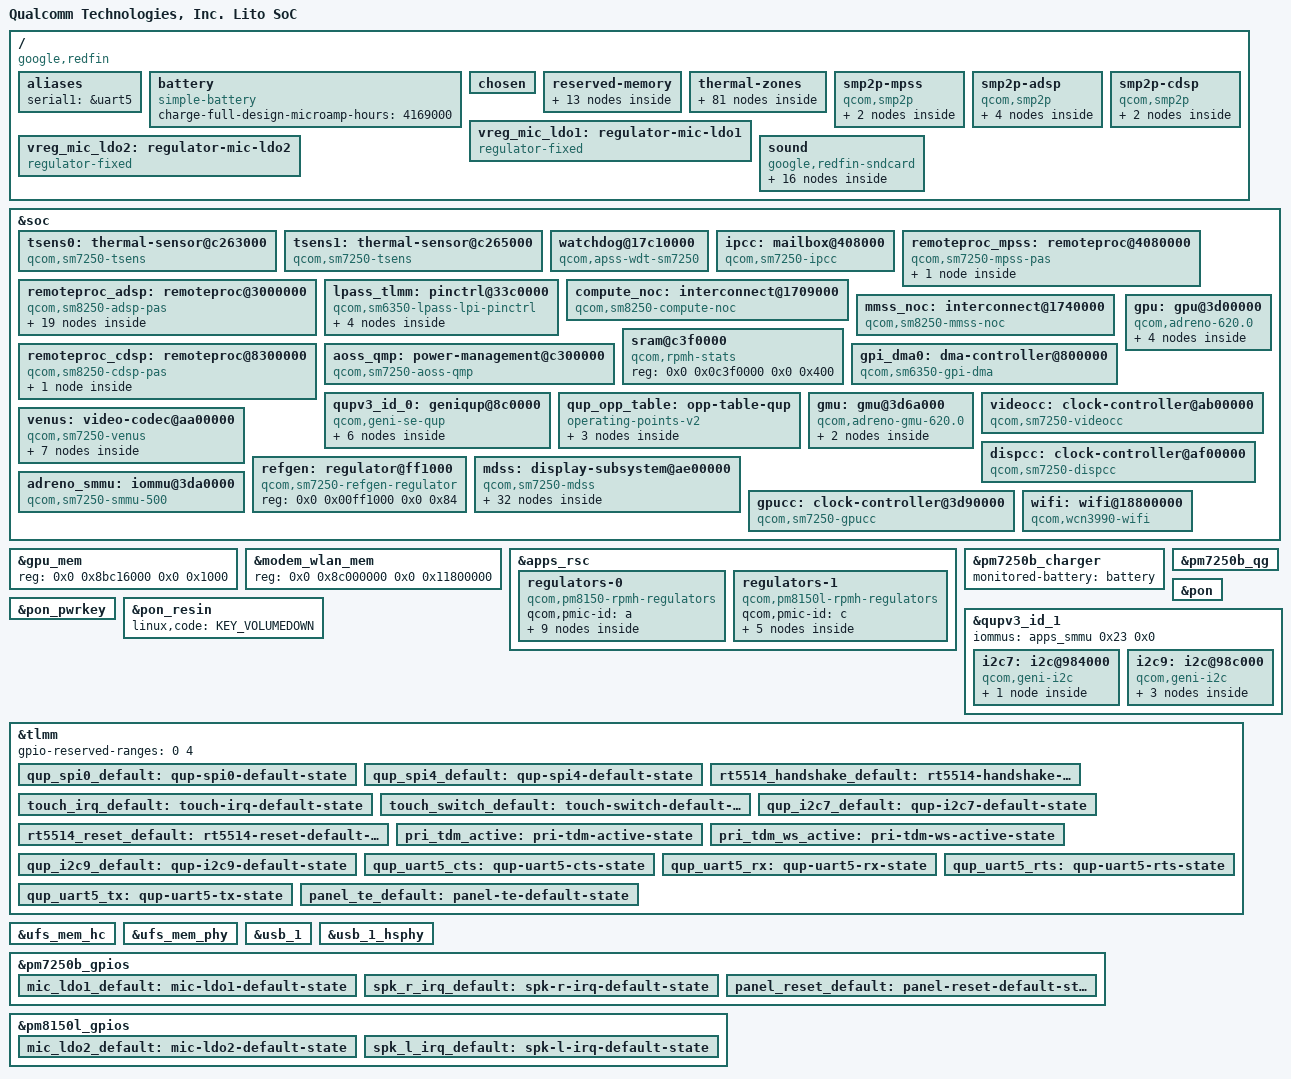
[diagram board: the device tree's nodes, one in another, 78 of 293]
// SPDX-License-Identifier: GPL-2.0-only
/*
 * Google Pixel 5 (redfin), SM7250. First-gate board file (P6.3): enough to
 * reach an initramfs over UFS + USB2 with a mainline kernel.
 *
 * Hardware values come from the DT the bootloader hands the stock 4.19
 * kernel (firmware/live.dtb: base DTB + dtbo overlay 25, Redfin PVT) and the
 * downstream sources (lito-redfin*.dtsi). See docs/research/mainline-boot.md.
 */
/dts-v1/;

#include <dt-bindings/dma/qcom-gpi.h>
#include <dt-bindings/arm/qcom,ids.h>
#include <dt-bindings/clock/qcom,dispcc-sm8250.h>
#include <dt-bindings/clock/qcom,dsi-phy-28nm.h>
#include <dt-bindings/clock/qcom,gpucc-sm8250.h>
#include <dt-bindings/clock/qcom,videocc-sm7250.h>
#include <dt-bindings/firmware/qcom,scm.h>
#include <dt-bindings/gpio/gpio.h>
#include <dt-bindings/input/input.h>
#include <dt-bindings/interconnect/qcom,sm8250.h>
#include <dt-bindings/interrupt-controller/arm-gic.h>
#include <dt-bindings/mailbox/qcom-ipcc.h>
#include <dt-bindings/pinctrl/qcom,pmic-gpio.h>
#include <dt-bindings/regulator/qcom,rpmh-regulator.h>
#include <dt-bindings/soc/qcom,apr.h>
#include <dt-bindings/sound/qcom,q6afe.h>
#include <dt-bindings/sound/qcom,q6asm.h>
#include "sm7250.dtsi"
#include "pm8150.dtsi"
#include "pm8150l.dtsi"

/* Live DT: qcom,pm7250b@2 and @3 on the SPMI bus */
#define PM7250B_SID 2
#define PM7250B_SID1 3
#include "pm7250b.dtsi"
#include "sm7250-google-redfin-dtbo-sink.dtsi"

/ {
	/*
	 * model, msm-id and board-id are exactly those of the stock base DTB
	 * in vendor_boot, which the bootloader is known to pick (Test 27).
	 * The dtbo overlay then replaces every existing root property: Linux
	 * sees model "Google Inc. MSM sm7250 v2 Redfin PVT" and compatible
	 * "google,redfin-sm7250", "qcom,sm7250" (live DT).
	 */
	model = "Qualcomm Technologies, Inc. Lito SoC";
	compatible = "google,redfin", "qcom,sm7250";
	chassis-type = "handset";
	qcom,msm-id = <QCOM_ID_SM7250 0x10000>, <440 0x10000>;
	qcom,board-id = <0 0>;

	/*
	 * Design capacity (downstream charge_full_design) and the cell's OCV
	 * tables, which qcom_qg needs. No voltage or current: qcom_smbx then
	 * keeps the float voltage the bootloader set (4.45 V downstream).
	 */
	aliases {
		/*
		 * qcom_geni_serial numbers high-speed UARTs after the highest
		 * serial alias; with none at all the port is refused ("Invalid
		 * line -19", Test 99).
		 */
		serial1 = &uart5;
	};

	battery: battery {
		compatible = "simple-battery";
		charge-full-design-microamp-hours = <4169000>;
		/*
		 * Generated at build time from firmware/live.dts by
		 * scripts/gen-battery-ocv.py (vendor data, not in git).
		 */
#include "sm7250-google-redfin-battery-ocv.dtsi"
	};

	/* The bootloader fills in bootargs, initrd, kaslr-seed (and cdt). */
	chosen {
	};

	reserved-memory {
		/*
		 * Fixed regions of the live DT that sm7250.dtsi does not reserve.
		 * The stock overlay's own carve-outs land in the sink, so all of
		 * them are repeated here.
		 */
		sec_apps_mem: sec-apps@808ff000 {
			reg = <0x0 0x808ff000 0x0 0x1000>;
			no-map;
		};

		qtee_apps_mem: qtee-apps@81e00000 {
			reg = <0x0 0x81e00000 0x0 0x2600000>;
			no-map;
		};

		pil_reserved_mem: pil-reserved@8bc17400 {
			reg = <0x0 0x8bc17400 0x0 0x3e8c00>;
			no-map;
		};

		/* Bootloader splash; also the display ramdump area */
		cont_splash_mem: cont-splash@a0000000 {
			reg = <0x0 0xa0000000 0x0 0x2300000>;
			no-map;
		};

		dfps_data_mem: dfps-data@a2300000 {
			reg = <0x0 0xa2300000 0x0 0x100000>;
			no-map;
		};

		debug_info_mem: debug-info@b7e01000 {
			reg = <0x0 0xb7e01000 0x0 0x40000>;
			no-map;
		};

		/*
		 * Stock ramoops, alt copy and metadata. Not used as pstore:
		 * neither a warm reboot nor a panic reboot keeps it (Test 28).
		 */
		ramoops_mem: ramoops@b7e41000 {
			reg = <0x0 0xb7e41000 0x0 0x400000>;
			no-map;
		};

		alt_ramoops_mem: alt-ramoops@b8241000 {
			reg = <0x0 0xb8241000 0x0 0x400000>;
			no-map;
		};

		/*
		 * Venus secure non-pixel pool: handed to VM CP_NON_PIXEL (0xb)
		 * at probe, so no-map. Encoder INTERNAL_PERSIST buffers come
		 * from it (64 KiB per 720p session).
		 */
		venus_np_mem: venus-non-pixel {
			size = <0x0 0x400000>;
			alignment = <0x0 0x100000>;
			no-map;
		};

		ramoops_meta_mem: ramoops-meta@b8641000 {
			reg = <0x0 0xb8641000 0x0 0x1000>;
			no-map;
		};

		ramdumplog_mem: ramdumplog@b8642000 {
			reg = <0x0 0xb8642000 0x0 0x10000>;
			no-map;
		};

		kregistry_mem: kregistry@c8000000 {
			reg = <0x0 0xc8000000 0x0 0x10000>;
			no-map;
		};

		/*
		 * Modem EFS buffer for rmtfs. Downstream allocates it at run time
		 * (live DT qcom,rmtfs_sharedmem: size only) and shares it with the
		 * modem (hyp_assign to HLOS + MSS_MSA); on redfin it lands at
		 * 0xf9900000 (downstream /sys/class/uio/uio0/maps/map0).
		 */
		rmtfs_mem: rmtfs@f9900000 {
			compatible = "qcom,rmtfs-mem";
			reg = <0x0 0xf9900000 0x0 0x280000>;
			no-map;

			qcom,client-id = <1>;
			qcom,vmid = <QCOM_SCM_VMID_MSS_MSA>;
		};
	};
};

&soc {
	/*
	 * The two TSENS controllers, as in the live DT (tsens@c222000 and
	 * tsens@c223000: SROT + TM regions, PDC 26/28 and 27/29). Their
	 * "tsens-0C" interrupt (PDC 20/21) is downstream-only.
	 */
	tsens0: thermal-sensor@c263000 {
		compatible = "qcom,sm7250-tsens", "qcom,tsens-v2";
		reg = <0x0 0x0c263000 0x0 0x1ff>,	/* TM */
		      <0x0 0x0c222000 0x0 0x1ff>;	/* SROT */
		#qcom,sensors = <15>;
		interrupts-extended = <&pdc 26 IRQ_TYPE_LEVEL_HIGH>,
				      <&pdc 28 IRQ_TYPE_LEVEL_HIGH>;
		interrupt-names = "uplow", "critical";
		#thermal-sensor-cells = <1>;
	};

	tsens1: thermal-sensor@c265000 {
		compatible = "qcom,sm7250-tsens", "qcom,tsens-v2";
		reg = <0x0 0x0c265000 0x0 0x1ff>,	/* TM */
		      <0x0 0x0c223000 0x0 0x1ff>;	/* SROT */
		#qcom,sensors = <12>;
		interrupts-extended = <&pdc 27 IRQ_TYPE_LEVEL_HIGH>,
				      <&pdc 29 IRQ_TYPE_LEVEL_HIGH>;
		interrupt-names = "uplow", "critical";
		#thermal-sensor-cells = <1>;
	};
};

/*
 * One zone per sensor, named and numbered as downstream
 * (vendor/qcom/lito-thermal.dtsi). Only a critical trip for now: 110 C
 * shuts the phone down. CPU throttling is the cpufreq-hw firmware's (LMh);
 * GPU and modem cooling come with those items.
 */
/ {
	thermal-zones {
		aoss0-thermal {
			thermal-sensors = <&tsens0 0>;

			trips {
				aoss0-crit {
					temperature = <110000>;
					hysteresis = <1000>;
					type = "critical";
				};
			};
		};

		cpu0-0-thermal {
			thermal-sensors = <&tsens0 1>;

			trips {
				cpu0-0-crit {
					temperature = <110000>;
					hysteresis = <1000>;
					type = "critical";
				};
			};
		};

		cpu0-1-thermal {
			thermal-sensors = <&tsens0 2>;

			trips {
				cpu0-1-crit {
					temperature = <110000>;
					hysteresis = <1000>;
					type = "critical";
				};
			};
		};

		cpu0-2-thermal {
			thermal-sensors = <&tsens0 3>;

			trips {
				cpu0-2-crit {
					temperature = <110000>;
					hysteresis = <1000>;
					type = "critical";
				};
			};
		};

		cpu0-3-thermal {
			thermal-sensors = <&tsens0 4>;

			trips {
				cpu0-3-crit {
					temperature = <110000>;
					hysteresis = <1000>;
					type = "critical";
				};
			};
		};

		cpu0-4-thermal {
			thermal-sensors = <&tsens0 5>;

			trips {
				cpu0-4-crit {
					temperature = <110000>;
					hysteresis = <1000>;
					type = "critical";
				};
			};
		};

		cpu0-5-thermal {
			thermal-sensors = <&tsens0 6>;

			trips {
				cpu0-5-crit {
					temperature = <110000>;
					hysteresis = <1000>;
					type = "critical";
				};
			};
		};

		cpuss0-thermal {
			thermal-sensors = <&tsens0 7>;

			trips {
				cpuss0-crit {
					temperature = <110000>;
					hysteresis = <1000>;
					type = "critical";
				};
			};
		};

		cpuss1-thermal {
			thermal-sensors = <&tsens0 8>;

			trips {
				cpuss1-crit {
					temperature = <110000>;
					hysteresis = <1000>;
					type = "critical";
				};
			};
		};

		cpu1-0-thermal {
			thermal-sensors = <&tsens0 9>;

			trips {
				cpu1-0-crit {
					temperature = <110000>;
					hysteresis = <1000>;
					type = "critical";
				};
			};
		};

		cpu1-1-thermal {
			thermal-sensors = <&tsens0 10>;

			trips {
				cpu1-1-crit {
					temperature = <110000>;
					hysteresis = <1000>;
					type = "critical";
				};
			};
		};

		cpu1-2-thermal {
			thermal-sensors = <&tsens0 11>;

			trips {
				cpu1-2-crit {
					temperature = <110000>;
					hysteresis = <1000>;
					type = "critical";
				};
			};
		};

		cpu1-3-thermal {
			thermal-sensors = <&tsens0 12>;

			trips {
				cpu1-3-crit {
					temperature = <110000>;
					hysteresis = <1000>;
					type = "critical";
				};
			};
		};

		gpuss0-thermal {
			thermal-sensors = <&tsens0 13>;

			trips {
				gpuss0-crit {
					temperature = <110000>;
					hysteresis = <1000>;
					type = "critical";
				};
			};
		};

		gpuss1-thermal {
			thermal-sensors = <&tsens0 14>;

			trips {
				gpuss1-crit {
					temperature = <110000>;
					hysteresis = <1000>;
					type = "critical";
				};
			};
		};

		aoss1-thermal {
			thermal-sensors = <&tsens1 0>;

			trips {
				aoss1-crit {
					temperature = <110000>;
					hysteresis = <1000>;
					type = "critical";
				};
			};
		};

		cwlan-thermal {
			thermal-sensors = <&tsens1 1>;

			trips {
				cwlan-crit {
					temperature = <110000>;
					hysteresis = <1000>;
					type = "critical";
				};
			};
		};

		video-thermal {
			thermal-sensors = <&tsens1 2>;

			trips {
				video-crit {
					temperature = <110000>;
					hysteresis = <1000>;
					type = "critical";
				};
			};
		};

		ddr-thermal {
			thermal-sensors = <&tsens1 3>;

			trips {
				ddr-crit {
					temperature = <110000>;
					hysteresis = <1000>;
					type = "critical";
				};
			};
		};

		q6-hvx-thermal {
			thermal-sensors = <&tsens1 4>;

			trips {
				q6-hvx-crit {
					temperature = <110000>;
					hysteresis = <1000>;
					type = "critical";
				};
			};
		};

		cmpss-thermal {
			thermal-sensors = <&tsens1 5>;

			trips {
				cmpss-crit {
					temperature = <110000>;
					hysteresis = <1000>;
					type = "critical";
				};
			};
		};

		npu-thermal {
			thermal-sensors = <&tsens1 6>;

			trips {
				npu-crit {
					temperature = <110000>;
					hysteresis = <1000>;
					type = "critical";
				};
			};
		};

		camera-thermal {
			thermal-sensors = <&tsens1 7>;

			trips {
				camera-crit {
					temperature = <110000>;
					hysteresis = <1000>;
					type = "critical";
				};
			};
		};

		mdm-vec-thermal {
			thermal-sensors = <&tsens1 8>;

			trips {
				mdm-vec-crit {
					temperature = <110000>;
					hysteresis = <1000>;
					type = "critical";
				};
			};
		};

		mdm-scl-thermal {
			thermal-sensors = <&tsens1 9>;

			trips {
				mdm-scl-crit {
					temperature = <110000>;
					hysteresis = <1000>;
					type = "critical";
				};
			};
		};

		mdm-core0-thermal {
			thermal-sensors = <&tsens1 10>;

			trips {
				mdm-core0-crit {
					temperature = <110000>;
					hysteresis = <1000>;
					type = "critical";
				};
			};
		};

		mdm-core1-thermal {
			thermal-sensors = <&tsens1 11>;

			trips {
				mdm-core1-crit {
					temperature = <110000>;
					hysteresis = <1000>;
					type = "critical";
				};
			};
		};
	};

	/* Live DT qcom,smp2p-mpss: SMEM items 435/428, IPCC client MPSS signal 2 */
	smp2p-mpss {
		compatible = "qcom,smp2p";
		qcom,smem = <435>, <428>;
		interrupts-extended = <&ipcc IPCC_CLIENT_MPSS IPCC_MPROC_SIGNAL_SMP2P
					     IRQ_TYPE_EDGE_RISING>;
		mboxes = <&ipcc IPCC_CLIENT_MPSS IPCC_MPROC_SIGNAL_SMP2P>;
		qcom,local-pid = <0>;
		qcom,remote-pid = <1>;

		modem_smp2p_out: master-kernel {
			qcom,entry-name = "master-kernel";
			#qcom,smem-state-cells = <1>;
		};

		modem_smp2p_in: slave-kernel {
			qcom,entry-name = "slave-kernel";
			interrupt-controller;
			#interrupt-cells = <2>;
		};
	};

	/* Live DT qcom,smp2p-adsp: SMEM items 443/429, IPCC client LPASS */
	smp2p-adsp {
		compatible = "qcom,smp2p";
		qcom,smem = <443>, <429>;
		interrupts-extended = <&ipcc IPCC_CLIENT_LPASS IPCC_MPROC_SIGNAL_SMP2P
					     IRQ_TYPE_EDGE_RISING>;
		mboxes = <&ipcc IPCC_CLIENT_LPASS IPCC_MPROC_SIGNAL_SMP2P>;
		qcom,local-pid = <0>;
		qcom,remote-pid = <2>;

		adsp_smp2p_out: master-kernel {
			qcom,entry-name = "master-kernel";
			#qcom,smem-state-cells = <1>;
		};

		adsp_smp2p_in: slave-kernel {
			qcom,entry-name = "slave-kernel";
			interrupt-controller;
			#interrupt-cells = <2>;
		};

		/*
		 * The AP's awake/asleep state for the ADSP sensors (SEE's
		 * remote_proc_state sensor): bit 12 set while awake (downstream
		 * smp2p_sleepstate.c). sleepstate_see: SEE asks to wake the AP.
		 */
		adsp_sleepstate_out: sleepstate-out {
			qcom,entry-name = "sleepstate";
			#qcom,smem-state-cells = <1>;
		};

		adsp_sleepstate_in: sleepstate-in {
			qcom,entry-name = "sleepstate_see";
			interrupt-controller;
			#interrupt-cells = <2>;
		};
	};

	/* Live DT qcom,smp2p-cdsp: SMEM items 94/432, IPCC client CDSP */
	smp2p-cdsp {
		compatible = "qcom,smp2p";
		qcom,smem = <94>, <432>;
		interrupts-extended = <&ipcc IPCC_CLIENT_CDSP IPCC_MPROC_SIGNAL_SMP2P
					     IRQ_TYPE_EDGE_RISING>;
		mboxes = <&ipcc IPCC_CLIENT_CDSP IPCC_MPROC_SIGNAL_SMP2P>;
		qcom,local-pid = <0>;
		qcom,remote-pid = <5>;

		cdsp_smp2p_out: master-kernel {
			qcom,entry-name = "master-kernel";
			#qcom,smem-state-cells = <1>;
		};

		cdsp_smp2p_in: slave-kernel {
			qcom,entry-name = "slave-kernel";
			interrupt-controller;
			#interrupt-cells = <2>;
		};
	};
};

/*
 * Zap shader region. The live DT reserves 0x8bc15400-0x8bc17400
 * (pil_gpu_region), but TZ only takes a page-aligned target for the zap
 * shader (nairo, same SoC): use the aligned page inside it.
 */
&gpu_mem {
	reg = <0x0 0x8bc16000 0x0 0x1000>;
};

/* Live DT: the redfin overlay grows the modem + WLAN region to 0x11800000. */
&modem_wlan_mem {
	reg = <0x0 0x8c000000 0x0 0x11800000>;
};

&soc {
	/* Same APSS watchdog block as SM8250 (live DT: qcom,wdt@17c10000). */
	watchdog@17c10000 {
		compatible = "qcom,apss-wdt-sm7250", "qcom,kpss-wdt";
		reg = <0x0 0x17c10000 0x0 0x1000>;
		clocks = <&sleep_clk>;
		interrupts = <GIC_SPI 0 IRQ_TYPE_EDGE_RISING>;
	};

	/* Live DT qcom,ipcc@408000 */
	ipcc: mailbox@408000 {
		compatible = "qcom,sm7250-ipcc", "qcom,ipcc";
		reg = <0x0 0x00408000 0x0 0x1000>;
		interrupts = <GIC_SPI 229 IRQ_TYPE_LEVEL_HIGH>;
		interrupt-controller;
		#interrupt-cells = <3>;
		#mbox-cells = <2>;
	};

	/*
	 * Live DT qcom,mss@4080000 (pil-tz-generic): PAS ID 4, wdog SPI 266,
	 * smp2p bits 0-3 and 7, CX + MSS proxy votes, signals the AOP, the
	 * modem + WLAN carve-out. auto_boot is off: userspace starts it.
	 */
	remoteproc_mpss: remoteproc@4080000 {
		compatible = "qcom,sm7250-mpss-pas";
		reg = <0x0 0x04080000 0x0 0x10000>;

		interrupts-extended = <&intc GIC_SPI 266 IRQ_TYPE_EDGE_RISING>,
				      <&modem_smp2p_in 0 IRQ_TYPE_EDGE_RISING>,
				      <&modem_smp2p_in 1 IRQ_TYPE_EDGE_RISING>,
				      <&modem_smp2p_in 2 IRQ_TYPE_EDGE_RISING>,
				      <&modem_smp2p_in 3 IRQ_TYPE_EDGE_RISING>,
				      <&modem_smp2p_in 7 IRQ_TYPE_EDGE_RISING>;
		interrupt-names = "wdog", "fatal", "ready", "handover",
				  "stop-ack", "shutdown-ack";

		clocks = <&rpmhcc RPMH_CXO_CLK>;
		clock-names = "xo";

		power-domains = <&rpmhpd RPMHPD_CX>, <&rpmhpd RPMHPD_MSS>;
		power-domain-names = "cx", "mss";

		memory-region = <&modem_wlan_mem>;
		firmware-name = "modem.mdt";	/* via firmware_class.path */

		qcom,qmp = <&aoss_qmp>;

		qcom,smem-states = <&modem_smp2p_out 0>;
		qcom,smem-state-names = "stop";

		glink-edge {
			interrupts-extended = <&ipcc IPCC_CLIENT_MPSS
						     IPCC_MPROC_SIGNAL_GLINK_QMP
						     IRQ_TYPE_EDGE_RISING>;
			mboxes = <&ipcc IPCC_CLIENT_MPSS IPCC_MPROC_SIGNAL_GLINK_QMP>;
			label = "modem";
			qcom,remote-pid = <1>;
		};
	};

	/*
	 * ADSP and CDSP (live DT qcom,lpass@3000000 PAS ID 1, qcom,turing@8300000
	 * PAS ID 18; nodes as nairo 0149). The SM8250 compatible matches the
	 * same PAS data until nairo 0121 (the SM7250 one) is in the series.
	 * The ADSP runs (Tests 119-131): pixel5-adsp.service starts it once its
	 * firmware is reachable (the probe-time auto boot fails), hexagonrpcd
	 * serves its sensor process, and the smp2p sleepstate entries keep
	 * Google's CHRE from crashing it. The CDSP stays disabled: TZ refuses
	 * its image (-22, Tests 115-118).
	 */
	remoteproc_adsp: remoteproc@3000000 {
		compatible = "qcom,sm8250-adsp-pas";
		reg = <0x0 0x03000000 0x0 0x100>;

		interrupts-extended = <&pdc 16 IRQ_TYPE_EDGE_RISING>,
				      <&adsp_smp2p_in 0 IRQ_TYPE_EDGE_RISING>,
				      <&adsp_smp2p_in 1 IRQ_TYPE_EDGE_RISING>,
				      <&adsp_smp2p_in 2 IRQ_TYPE_EDGE_RISING>,
				      <&adsp_smp2p_in 3 IRQ_TYPE_EDGE_RISING>;
		interrupt-names = "wdog", "fatal", "ready", "handover", "stop-ack";

		clocks = <&rpmhcc RPMH_CXO_CLK>;
		clock-names = "xo";

		power-domains = <&rpmhpd RPMHPD_LCX>, <&rpmhpd RPMHPD_LMX>;
		power-domain-names = "lcx", "lmx";

		memory-region = <&adsp_mem>;

		qcom,qmp = <&aoss_qmp>;

		qcom,smem-states = <&adsp_smp2p_out 0>;
		qcom,smem-state-names = "stop";

		glink-edge {
			interrupts-extended = <&ipcc IPCC_CLIENT_LPASS
						     IPCC_MPROC_SIGNAL_GLINK_QMP
						     IRQ_TYPE_EDGE_RISING>;
			mboxes = <&ipcc IPCC_CLIENT_LPASS IPCC_MPROC_SIGNAL_GLINK_QMP>;
			label = "lpass";
			qcom,remote-pid = <2>;

			/*
			 * FastRPC: the sensor PD reads its registry and config
			 * through it (served by a userspace daemon). Context
			 * banks from the live DT adsprpc-smd: SIDs 0x1403-0x1405,
			 * the last one shared (5 sessions); shape as sm6350.
			 */
			fastrpc {
				compatible = "qcom,fastrpc";
				qcom,glink-channels = "fastrpcglink-apps-dsp";
				label = "adsp";
				qcom,non-secure-domain;
				#address-cells = <1>;
				#size-cells = <0>;

				compute-cb@3 {
					compatible = "qcom,fastrpc-compute-cb";
					reg = <3>;
					iommus = <&apps_smmu 0x1403 0x0>;
				};

				compute-cb@4 {
					compatible = "qcom,fastrpc-compute-cb";
					reg = <4>;
					iommus = <&apps_smmu 0x1404 0x0>;
				};

				compute-cb@5 {
					compatible = "qcom,fastrpc-compute-cb";
					reg = <5>;
					iommus = <&apps_smmu 0x1405 0x0>;
					qcom,nsessions = <5>;
				};
			};

			/*
			 * Audio: the ADSP runs Elite with APR (live DT
			 * qcom,msm-audio-apr; audio-ion SMMU stream 0x1401).
			 * Services as nairo 0149 (sm7250.dtsi).
			 */
			apr {
				compatible = "qcom,apr-v2";
				qcom,glink-channels = "apr_audio_svc";
				qcom,domain = <APR_DOMAIN_ADSP>;
				#address-cells = <1>;
				#size-cells = <0>;

				service@3 {
					reg = <APR_SVC_ADSP_CORE>;
					compatible = "qcom,q6core";
					qcom,protection-domain = "avs/audio", "msm/adsp/audio_pd";
				};

				q6afe: service@4 {
					compatible = "qcom,q6afe";
					reg = <APR_SVC_AFE>;
					qcom,protection-domain = "avs/audio", "msm/adsp/audio_pd";

					q6afedai: dais {
						compatible = "qcom,q6afe-dais";
						#address-cells = <1>;
						#size-cells = <0>;
						#sound-dai-cells = <1>;
					};

					q6afecc: clock-controller {
						compatible = "qcom,q6afe-clocks";
						#clock-cells = <2>;
					};
				};

				q6asm: service@7 {
					compatible = "qcom,q6asm";
					reg = <APR_SVC_ASM>;
					qcom,protection-domain = "avs/audio", "msm/adsp/audio_pd";

					q6asmdai: dais {
						compatible = "qcom,q6asm-dais";
						#address-cells = <1>;
						#size-cells = <0>;
						#sound-dai-cells = <1>;
						iommus = <&apps_smmu 0x1401 0x0>;
					};
				};

				q6adm: service@8 {
					compatible = "qcom,q6adm";
					reg = <APR_SVC_ADM>;
					qcom,protection-domain = "avs/audio", "msm/adsp/audio_pd";

					q6routing: routing {
						compatible = "qcom,q6adm-routing";
						#sound-dai-cells = <0>;
					};
				};
			};
		};
	};

	/*
	 * LPASS LPI TLMM (downstream lito-lpi: qcom,lpi-pinctrl at 0x33c0000,
	 * slew 0x355a000). 15 pins laid out as SM6350's (nairo 0150). The
	 * quinary TDM to the speaker amps uses LPI GPIOs 6-9 (downstream
	 * lpi_i2s1_*, drive 16 mA in lito-redfin-audio).
	 */
	lpass_tlmm: pinctrl@33c0000 {
		compatible = "qcom,sm6350-lpass-lpi-pinctrl";
		reg = <0x0 0x033c0000 0x0 0x20000>,
		      <0x0 0x03550000 0x0 0x10000>;
		gpio-controller;
		#gpio-cells = <2>;
		gpio-ranges = <&lpass_tlmm 0 0 15>;

		clocks = <&q6afecc LPASS_HW_MACRO_VOTE LPASS_CLK_ATTRIBUTE_COUPLE_NO>,
			 <&q6afecc LPASS_HW_DCODEC_VOTE LPASS_CLK_ATTRIBUTE_COUPLE_NO>;
		clock-names = "core", "audio";

		quin_tdm_active: quin-tdm-active-state {
			clk-pins {
				pins = "gpio6";
				function = "i2s1_clk";
				drive-strength = <16>;
				bias-disable;
			};

			ws-pins {
				pins = "gpio7";
				function = "i2s1_ws";
				drive-strength = <16>;
				bias-disable;
			};

			data-pins {
				pins = "gpio8", "gpio9";
				function = "i2s1_data";
				drive-strength = <16>;
				bias-disable;
			};
		};
	};

	/*
	 * Compute NoC: SM7250 has SM8250's (downstream lito-bus: same
	 * nodes qnm_npu -> qns_cdsp_gemnoc, same BCMs CO0/CO2). Base from
	 * lito-bus (compute_noc 0x1700000 + 0x9000); no QoS is programmed.
	 */
	compute_noc: interconnect@1709000 {
		compatible = "qcom,sm8250-compute-noc";
		reg = <0x0 0x01709000 0x0 0x1000>;
		#interconnect-cells = <2>;
		qcom,bcm-voters = <&apps_bcm_voter>;
	};

	/*
	 * MMSS NoC: SM7250 has SM8250's video nodes (downstream lito-bus:
	 * qxm_venus0/1/arm9 -> qns_mem_noc_sf, BCMs MM3/MM2). Base and size
	 * from lito-bus (mmss_noc-base 0x1740000, 0x1c100); no QoS is
	 * programmed. Only Venus votes on it; MM0 (display HF) is keepalive.
	 */
	mmss_noc: interconnect@1740000 {
		compatible = "qcom,sm8250-mmss-noc";
		reg = <0x0 0x01740000 0x0 0x1c100>;
		#interconnect-cells = <2>;
		qcom,bcm-voters = <&apps_bcm_voter>;
	};

	remoteproc_cdsp: remoteproc@8300000 {
		compatible = "qcom,sm8250-cdsp-pas";
		reg = <0x0 0x08300000 0x0 0x10000>;

		/* downstream turing: NPU -> CDSP GEM NoC, ib 1 KB/s, while booting */
		interconnects = <&compute_noc MASTER_NPU 0 &compute_noc SLAVE_CDSP_MEM_NOC 0>;

		interrupts-extended = <&intc GIC_SPI 578 IRQ_TYPE_EDGE_RISING>,
				      <&cdsp_smp2p_in 0 IRQ_TYPE_EDGE_RISING>,
				      <&cdsp_smp2p_in 1 IRQ_TYPE_EDGE_RISING>,
				      <&cdsp_smp2p_in 2 IRQ_TYPE_EDGE_RISING>,
				      <&cdsp_smp2p_in 3 IRQ_TYPE_EDGE_RISING>;
		interrupt-names = "wdog", "fatal", "ready", "handover", "stop-ack";

		clocks = <&rpmhcc RPMH_CXO_CLK>;
		clock-names = "xo";

		power-domains = <&rpmhpd RPMHPD_CX>;
		power-domain-names = "cx";

		memory-region = <&cdsp_mem>;

		qcom,qmp = <&aoss_qmp>;

		qcom,smem-states = <&cdsp_smp2p_out 0>;
		qcom,smem-state-names = "stop";

		glink-edge {
			interrupts-extended = <&ipcc IPCC_CLIENT_CDSP
						     IPCC_MPROC_SIGNAL_GLINK_QMP
						     IRQ_TYPE_EDGE_RISING>;
			mboxes = <&ipcc IPCC_CLIENT_CDSP IPCC_MPROC_SIGNAL_GLINK_QMP>;
			label = "cdsp";
			qcom,remote-pid = <5>;
		};
	};

	/* Live DT qcom,qmp-aop@c300000: IPCC client AOP, signal 0 */
	aoss_qmp: power-management@c300000 {
		compatible = "qcom,sm7250-aoss-qmp", "qcom,aoss-qmp";
		reg = <0x0 0x0c300000 0x0 0x1000>;
		interrupts-extended = <&ipcc IPCC_CLIENT_AOP IPCC_MPROC_SIGNAL_GLINK_QMP
					     IRQ_TYPE_EDGE_RISING>;
		mboxes = <&ipcc IPCC_CLIENT_AOP IPCC_MPROC_SIGNAL_GLINK_QMP>;
		#clock-cells = <0>;
	};

	/*
	 * AOP sleep statistics (AOSS sleep, CX collapse, DDR): the live DT
	 * qcom,rpm-stats reads its offset word at 0xc3f0004, the layout
	 * mainline's qcom,rpmh-stats reads on sm8250/sm6350/sc7180.
	 */
	sram@c3f0000 {
		compatible = "qcom,rpmh-stats";
		reg = <0x0 0x0c3f0000 0x0 0x400>;
	};

	/*
	 * QUP wrapper 0 GPI DMA (live DT qcom,gpi-dma@800000: SPI 244-253,
	 * 5 channels for the AP, EE offset 0x10000, SMMU stream 0x4f6); the
	 * SM6350 block is the same. SE4's FIFO is disabled by firmware, so it
	 * needs this.
	 */
	gpi_dma0: dma-controller@800000 {
		compatible = "qcom,sm6350-gpi-dma";
		reg = <0x0 0x00800000 0x0 0x60000>;
		interrupts = <GIC_SPI 244 IRQ_TYPE_LEVEL_HIGH>,
			     <GIC_SPI 245 IRQ_TYPE_LEVEL_HIGH>,
			     <GIC_SPI 246 IRQ_TYPE_LEVEL_HIGH>,
			     <GIC_SPI 247 IRQ_TYPE_LEVEL_HIGH>,
			     <GIC_SPI 248 IRQ_TYPE_LEVEL_HIGH>,
			     <GIC_SPI 249 IRQ_TYPE_LEVEL_HIGH>,
			     <GIC_SPI 250 IRQ_TYPE_LEVEL_HIGH>,
			     <GIC_SPI 251 IRQ_TYPE_LEVEL_HIGH>,
			     <GIC_SPI 252 IRQ_TYPE_LEVEL_HIGH>,
			     <GIC_SPI 253 IRQ_TYPE_LEVEL_HIGH>;
		dma-channels = <10>;
		dma-channel-mask = <0x1f>;
		iommus = <&apps_smmu 0x4f6 0x0>;
		#dma-cells = <3>;
	};

	/*
	 * QUP wrapper 0 (live DT qcom,qupv3_0_geni_se@8c0000, SMMU stream
	 * 0x4e3). Only SE0 and SE5 are described: SE1 (0x884000, GPIOs 0-3)
	 * belongs to TrustZone, see &tlmm.
	 */
	qupv3_id_0: geniqup@8c0000 {
		compatible = "qcom,geni-se-qup";
		reg = <0x0 0x008c0000 0x0 0x6000>;
		clock-names = "m-ahb", "s-ahb";
		clocks = <&gcc GCC_QUPV3_WRAP_0_M_AHB_CLK>,
			 <&gcc GCC_QUPV3_WRAP_0_S_AHB_CLK>;
		iommus = <&apps_smmu 0x4e3 0x0>;
		#address-cells = <2>;
		#size-cells = <2>;
		ranges;

		/*
		 * Touch SPI (downstream lito-qupv3 qupv3_se0_spi + redfin-touch:
		 * SPI 601, pins 42-45 function qup00, drive 6). No GPI DMA
		 * described: spi-geni-qcom then uses FIFO/SE DMA.
		 */
		spi0: spi@880000 {
			compatible = "qcom,geni-spi";
			reg = <0x0 0x00880000 0x0 0x4000>;
			clock-names = "se";
			clocks = <&gcc GCC_QUPV3_WRAP0_S0_CLK>;
			interrupts = <GIC_SPI 601 IRQ_TYPE_LEVEL_HIGH>;
			power-domains = <&rpmhpd RPMHPD_CX>;
			operating-points-v2 = <&qup_opp_table>;
			pinctrl-names = "default";
			pinctrl-0 = <&qup_spi0_default>;
			#address-cells = <1>;
			#size-cells = <0>;

			/*
			 * Samsung S6SY79x (downstream "sec,sec_ts", firmware
			 * s6sy79x.bin in the IC's flash): the S6SY761 command
			 * set over SPI (local patch 0005). Mode 3, 10 MHz,
			 * IRQ GPIO 9 level low, reset GPIO 8 (pulsed low),
			 * avdd L17A 3.304 V; no dvdd (commented out downstream).
			 * GPIO 35 selects the bus master: low = AP (pinctrl).
			 */
			touchscreen@0 {
				compatible = "samsung,s6sy761";
				reg = <0>;
				spi-max-frequency = <10000000>;
				spi-cpol;
				spi-cpha;
				interrupts-extended = <&tlmm 9 IRQ_TYPE_LEVEL_LOW>;
				reset-gpios = <&tlmm 8 GPIO_ACTIVE_LOW>;
				avdd-supply = <&vreg_l17a_3p3>;
				pinctrl-names = "default";
				pinctrl-0 = <&touch_irq_default>,
					    <&touch_switch_default>;
				touchscreen-size-x = <1080>;
				touchscreen-size-y = <2340>;
			};
		};

		/*
		 * RT5514 DSP SPI port (downstream lito-qupv3 qupv3_se4_spi +
		 * lito-redbull-audio mnh-spi@0: SPI 605, pins 29-32 function
		 * qup04, drive 6; mode 3, 20 MHz on the RT5514P, 10 MHz here).
		 * Used to load the DSP firmware, see &rt5514. Receive-only
		 * transfers return zeros on this GPI DMA path (Test 171):
		 * rt5514-spi reads full-duplex (local patch 0009).
		 */
		spi4: spi@890000 {
			compatible = "qcom,geni-spi";
			reg = <0x0 0x00890000 0x0 0x4000>;
			clock-names = "se";
			clocks = <&gcc GCC_QUPV3_WRAP0_S4_CLK>;
			interrupts = <GIC_SPI 605 IRQ_TYPE_LEVEL_HIGH>;
			power-domains = <&rpmhpd RPMHPD_CX>;
			operating-points-v2 = <&qup_opp_table>;
			pinctrl-names = "default";
			pinctrl-0 = <&qup_spi4_default>;
			dmas = <&gpi_dma0 0 4 QCOM_GPI_SPI>,
			       <&gpi_dma0 1 4 QCOM_GPI_SPI>;
			dma-names = "tx", "rx";
			#address-cells = <1>;
			#size-cells = <0>;

			/*
			 * No IRQ (TLMM 65, hotword events) for now. TLMM 66 is
			 * the AP's "SPI wanted" handshake to the CHRE, held
			 * high; its ack (TLMM 11) is not used.
			 */
			audio-codec@0 {
				compatible = "realtek,rt5514";
				reg = <0>;
				spi-max-frequency = <10000000>;
				spi-cpol;
				spi-cpha;
				pinctrl-names = "default";
				pinctrl-0 = <&rt5514_handshake_default>;
			};
		};

		/*
		 * Bluetooth UART (live DT qcom,qup_uart@894000, SPI 606,
		 * pins 38-41 function qup05; the TLMM 41 wakeup IRQ is left
		 * out for now).
		 */
		uart5: serial@894000 {
			compatible = "qcom,geni-uart";
			reg = <0x0 0x00894000 0x0 0x4000>;
			clock-names = "se";
			clocks = <&gcc GCC_QUPV3_WRAP0_S5_CLK>;
			interrupts = <GIC_SPI 606 IRQ_TYPE_LEVEL_HIGH>;
			power-domains = <&rpmhpd RPMHPD_CX>;
			operating-points-v2 = <&qup_opp_table>;
			pinctrl-names = "default";
			pinctrl-0 = <&qup_uart5_cts>, <&qup_uart5_rts>,
				    <&qup_uart5_tx>, <&qup_uart5_rx>;

			/*
			 * WCN3990 BT (live DT bt_wcn3990): io pm8150 S4,
			 * xtal pm8150 L14, core pm8150a L2, PA pm8150a L10.
			 * Firmware qca/crbtfw32.tlv + crnv32.bin (vendor).
			 */
			bluetooth {
				compatible = "qcom,wcn3991-bt";
				vddio-supply = <&vreg_s4a_1p8>;
				vddxo-supply = <&vreg_l14a_1p88>;
				vddrf-supply = <&vreg_l2c_1p3>;
				vddch0-supply = <&vreg_l10c_3p3>;
				max-speed = <3200000>;
			};
		};
	};

	/* QUP SE clock levels (as sm8250.dtsi) */
	qup_opp_table: opp-table-qup {
		compatible = "operating-points-v2";

		opp-50000000 {
			opp-hz = /bits/ 64 <50000000>;
			required-opps = <&rpmhpd_opp_min_svs>;
		};

		opp-75000000 {
			opp-hz = /bits/ 64 <75000000>;
			required-opps = <&rpmhpd_opp_low_svs>;
		};

		opp-120000000 {
			opp-hz = /bits/ 64 <120000000>;
			required-opps = <&rpmhpd_opp_svs>;
		};
	};

	/*
	 * Adreno 620 (live DT qcom,kgsl-3d0@3d00000: regs, SPI 300, SMMU
	 * stream 0 mask 0x401; RSCC at 0x3de0000). Only the two levels all
	 * three downstream speed bins share: 400 MHz SVS, 275 MHz LOW_SVS
	 * (lito-gpu.dtsi), until the speed-bin fuse is read.
	 */
	gpu: gpu@3d00000 {
		compatible = "qcom,adreno-620.0", "qcom,adreno";
		reg = <0x0 0x03d00000 0x0 0x40000>;
		reg-names = "kgsl_3d0_reg_memory";
		interrupts = <GIC_SPI 300 IRQ_TYPE_LEVEL_HIGH>;
		iommus = <&adreno_smmu 0 0x401>;
		operating-points-v2 = <&gpu_opp_table>;
		qcom,gmu = <&gmu>;
		#cooling-cells = <2>;

		zap-shader {
			memory-region = <&gpu_mem>;
			firmware-name = "a620_zap.mdt";	/* vendor, via firmware_class.path */
		};

		gpu_opp_table: opp-table {
			compatible = "operating-points-v2";

			opp-400000000 {
				opp-hz = /bits/ 64 <400000000>;
				opp-level = <RPMH_REGULATOR_LEVEL_SVS>;
			};

			opp-275000000 {
				opp-hz = /bits/ 64 <275000000>;
				opp-level = <RPMH_REGULATOR_LEVEL_LOW_SVS>;
			};
		};
	};

	/* Live DT qcom,gmu@3d6a000: GMU, PDC cfg + seq, SPI 304/305 */
	gmu: gmu@3d6a000 {
		compatible = "qcom,adreno-gmu-620.0", "qcom,adreno-gmu";
		reg = <0x0 0x03d6a000 0x0 0x30000>,
		      <0x0 0x03de0000 0x0 0x10000>,
		      <0x0 0x0b290000 0x0 0x10000>,
		      <0x0 0x0b490000 0x0 0x10000>;
		reg-names = "gmu", "rscc", "gmu_pdc", "gmu_pdc_seq";
		interrupts = <GIC_SPI 304 IRQ_TYPE_LEVEL_HIGH>,
			     <GIC_SPI 305 IRQ_TYPE_LEVEL_HIGH>;
		interrupt-names = "hfi", "gmu";
		clocks = <&gpucc GPU_CC_AHB_CLK>,
			 <&gpucc GPU_CC_CX_GMU_CLK>,
			 <&gpucc GPU_CC_CXO_CLK>,
			 <&gcc GCC_DDRSS_GPU_AXI_CLK>,
			 <&gcc GCC_GPU_MEMNOC_GFX_CLK>;
		clock-names = "ahb", "gmu", "cxo", "axi", "memnoc";
		power-domains = <&gpucc GPU_CX_GDSC>, <&gpucc GPU_GX_GDSC>;
		power-domain-names = "cx", "gx";
		iommus = <&adreno_smmu 5 0x400>;
		operating-points-v2 = <&gmu_opp_table>;

		gmu_opp_table: opp-table {
			compatible = "operating-points-v2";

			opp-200000000 {
				opp-hz = /bits/ 64 <200000000>;
				opp-level = <RPMH_REGULATOR_LEVEL_LOW_SVS>;
			};
		};
	};

	/*
	 * Display clock controller (live DT qcom,dispcc@af00000; node as
	 * nairo 0088). With it Linux owns the MDSS GDSC and the display
	 * clocks the bootloader leaves running after the splash. The DP PHY
	 * clocks are not described (no DisplayPort).
	 */
	/*
	 * Video clock controller: SM8150's layout with a Lucid PLL
	 * (downstream videocc-lito.c, local driver videocc-sm7250). On CX,
	 * as downstream (vdd_cx-supply). GCC_VIDEO_AHB_CLK is always on.
	 */
	videocc: clock-controller@ab00000 {
		compatible = "qcom,sm7250-videocc";
		reg = <0x0 0x0ab00000 0x0 0x10000>;
		power-domains = <&rpmhpd RPMHPD_CX>;
		required-opps = <&rpmhpd_opp_low_svs>;
		clocks = <&rpmhcc RPMH_CXO_CLK>;
		clock-names = "bi_tcxo";
		#clock-cells = <1>;
		#reset-cells = <1>;
		#power-domain-cells = <1>;
	};

	/*
	 * Venus (IRIS1, 2 pipes), from downstream lito-vidc.dtsi
	 * (qcom,vidc0) and the PIL node venus@aae0000 (PAS 9, video_mem).
	 * Non-secure context bank: SIDs 0x1380/0x60 and 0x1360.
	 * Interconnects inside the MMSS NoC only (no SM7250 GEM/config NoC
	 * provider yet): video-mem = downstream venus-ddr (VIDEO_P0), and
	 * "cpu-cfg" carries downstream's arm9-ddr vote (VIDEO_PROC, the
	 * same 1000 kbps venus puts on cpu-cfg); the real CPU -> VENUS_CFG
	 * path needs the GEM and config NoCs.
	 */
	venus: video-codec@aa00000 {
		compatible = "qcom,sm7250-venus";
		reg = <0x0 0x0aa00000 0x0 0x100000>;
		interrupts = <GIC_SPI 174 IRQ_TYPE_LEVEL_HIGH>;

		/* mvs1 is the CVP core: the encoder's VPSS runs there */
		power-domains = <&videocc MVSC_GDSC>,
				<&videocc MVS0_GDSC>,
				<&videocc MVS1_GDSC>,
				<&rpmhpd RPMHPD_CX>;
		power-domain-names = "venus", "vcodec0", "vcodec1", "cx";
		operating-points-v2 = <&venus_opp_table>;

		clocks = <&videocc VIDEO_CC_MVSC_CORE_CLK>,
			 <&videocc VIDEO_CC_VENUS_AHB_CLK>,
			 <&videocc VIDEO_CC_MVSC_CTL_AXI_CLK>,
			 <&gcc GCC_VIDEO_AXI_CLK>,
			 <&videocc VIDEO_CC_MVS0_CORE_CLK>,
			 <&videocc VIDEO_CC_MVS0_AXI_CLK>,
			 <&videocc VIDEO_CC_MVS1_CORE_CLK>,
			 <&videocc VIDEO_CC_MVS1_AXI_CLK>;
		clock-names = "core", "iface", "bus", "gcc_axi",
			      "vcodec0_core", "vcodec0_bus",
			      "vcodec1_core", "vcodec1_bus";

		interconnects = <&mmss_noc MASTER_VIDEO_P0 0 &mmss_noc SLAVE_MNOC_SF_MEM_NOC 0>,
				<&mmss_noc MASTER_VIDEO_PROC 0 &mmss_noc SLAVE_MNOC_SF_MEM_NOC 0>;
		interconnect-names = "video-mem", "cpu-cfg";

		iommus = <&apps_smmu 0x1380 0x60>,
			 <&apps_smmu 0x1360 0x0>;
		memory-region = <&video_mem>;

		video-decoder {
			compatible = "venus-decoder";
		};

		video-encoder {
			compatible = "venus-encoder";
		};

		/*
		 * Secure non-pixel stream (downstream venus_sec_non_pixel): the
		 * encoder's CVP core reads INTERNAL_PERSIST through it. Its
		 * page tables are shared with the VM (qcom,iommu-vmid).
		 */
		non-pixel {
			iommus = <&apps_smmu 0x1304 0xe0>;
			qcom,iommu-vmid = <0xb>;
			memory-region = <&venus_np_mem>;
		};

		/* SKU 0 rates; CX corners from videocc-lito rate_max */
		venus_opp_table: opp-table {
			compatible = "operating-points-v2";

			opp-240000000 {
				opp-hz = /bits/ 64 <240000000>;
				required-opps = <&rpmhpd_opp_low_svs>;
			};

			opp-338000000 {
				opp-hz = /bits/ 64 <338000000>;
				required-opps = <&rpmhpd_opp_svs>;
			};

			opp-365000000 {
				opp-hz = /bits/ 64 <365000000>;
				required-opps = <&rpmhpd_opp_svs_l1>;
			};
		};
	};

	dispcc: clock-controller@af00000 {
		compatible = "qcom,sm7250-dispcc";
		reg = <0x0 0x0af00000 0x0 0x20000>;
		power-domains = <&rpmhpd RPMHPD_CX>;
		required-opps = <&rpmhpd_opp_low_svs>;
		clocks = <&rpmhcc RPMH_CXO_CLK>,
			 <&gcc GCC_DISP_GPLL0_CLK_SRC>,
			 <&mdss_dsi0_phy DSI_BYTE_PLL_CLK>,
			 <&mdss_dsi0_phy DSI_PIXEL_PLL_CLK>,
			 <&mdss_dsi1_phy DSI_BYTE_PLL_CLK>,
			 <&mdss_dsi1_phy DSI_PIXEL_PLL_CLK>,
			 <0>, <0>;
		clock-names = "bi_tcxo",
			      "gcc_disp_gpll0_clk_src",
			      "dsi0_phy_pll_out_byteclk",
			      "dsi0_phy_pll_out_dsiclk",
			      "dsi1_phy_pll_out_byteclk",
			      "dsi1_phy_pll_out_dsiclk",
			      "dp_phy_pll_link_clk",
			      "dp_phy_pll_vco_div_clk";
		#clock-cells = <1>;
		#reset-cells = <1>;
		#power-domain-cells = <1>;
	};

	/* DSI reference voltage generator (live DT refgen; nairo 0098) */
	refgen: regulator@ff1000 {
		compatible = "qcom,sm7250-refgen-regulator",
			     "qcom,sm8250-refgen-regulator";
		reg = <0x0 0x00ff1000 0x0 0x84>;
	};

	/*
	 * Display subsystem: MDSS, DPU and both DSI controllers and 7 nm
	 * PHYs, as nairo 0098 (its sm7250.dtsi hunk does not apply on our
	 * base, as with dispcc). Addresses, interrupts and the SMMU stream
	 * (0xb40/0x402) agree with the downstream lito-sde.dtsi.
	 */
	mdss: display-subsystem@ae00000 {
		compatible = "qcom,sm7250-mdss";
		reg = <0x0 0x0ae00000 0x0 0x1000>;
		reg-names = "mdss";

		/*
		 * No interconnects: this tree has no SM7250 interconnect
		 * provider yet (nairo 0079-0082), as for the GPU. msm then
		 * skips its bandwidth votes and relies on what the bootloader
		 * left. nairo 0098 has mdp0-mem, mdp1-mem and cpu-cfg paths.
		 */

		power-domains = <&dispcc MDSS_GDSC>;

		clocks = <&dispcc DISP_CC_MDSS_AHB_CLK>,
			 <&gcc GCC_DISP_HF_AXI_CLK>,
			 <&gcc GCC_DISP_SF_AXI_CLK>,
			 <&dispcc DISP_CC_MDSS_MDP_CLK>;
		clock-names = "iface", "bus", "nrt_bus", "core";

		resets = <&dispcc DISP_CC_MDSS_CORE_BCR>;

		interrupts = <GIC_SPI 83 IRQ_TYPE_LEVEL_HIGH>;
		interrupt-controller;
		#interrupt-cells = <1>;

		iommus = <&apps_smmu 0xb40 0x402>;

		#address-cells = <2>;
		#size-cells = <2>;
		ranges;

		status = "okay";

		mdss_mdp: display-controller@ae01000 {
			compatible = "qcom,sm7250-dpu";
			reg = <0x0 0x0ae01000 0x0 0x8f000>,
			      <0x0 0x0aeb0000 0x0 0x2008>;
			reg-names = "mdp", "vbif";

			clocks = <&dispcc DISP_CC_MDSS_AHB_CLK>,
				 <&gcc GCC_DISP_HF_AXI_CLK>,
				 <&dispcc DISP_CC_MDSS_MDP_CLK>,
				 <&dispcc DISP_CC_MDSS_VSYNC_CLK>;
			clock-names = "iface", "bus", "core", "vsync";

			assigned-clocks = <&dispcc DISP_CC_MDSS_VSYNC_CLK>;
			assigned-clock-rates = <19200000>;

			operating-points-v2 = <&mdp_opp_table>;
			power-domains = <&rpmhpd RPMHPD_CX>;

			interrupt-parent = <&mdss>;
			interrupts = <0>;

			ports {
				#address-cells = <1>;
				#size-cells = <0>;

				port@0 {
					reg = <0>;
					dpu_intf1_out: endpoint {
						remote-endpoint = <&mdss_dsi0_in>;
					};
				};

				port@1 {
					reg = <1>;
					dpu_intf2_out: endpoint {
						remote-endpoint = <&mdss_dsi1_in>;
					};
				};
			};

			mdp_opp_table: opp-table {
				compatible = "operating-points-v2";

				opp-200000000 {
					opp-hz = /bits/ 64 <200000000>;
					required-opps = <&rpmhpd_opp_low_svs>;
				};

				opp-300000000 {
					opp-hz = /bits/ 64 <300000000>;
					required-opps = <&rpmhpd_opp_svs>;
				};

				opp-345000000 {
					opp-hz = /bits/ 64 <345000000>;
					required-opps = <&rpmhpd_opp_svs_l1>;
				};

				opp-460000000 {
					opp-hz = /bits/ 64 <460000000>;
					required-opps = <&rpmhpd_opp_nom>;
				};
			};
		};

		mdss_dsi0: dsi@ae94000 {
			compatible = "qcom,sm7250-dsi-ctrl",
				     "qcom,mdss-dsi-ctrl";
			reg = <0x0 0x0ae94000 0x0 0x400>;
			reg-names = "dsi_ctrl";

			interrupt-parent = <&mdss>;
			interrupts = <4>;

			clocks = <&dispcc DISP_CC_MDSS_BYTE0_CLK>,
				 <&dispcc DISP_CC_MDSS_BYTE0_INTF_CLK>,
				 <&dispcc DISP_CC_MDSS_PCLK0_CLK>,
				 <&dispcc DISP_CC_MDSS_ESC0_CLK>,
				 <&dispcc DISP_CC_MDSS_AHB_CLK>,
				 <&gcc GCC_DISP_HF_AXI_CLK>;
			clock-names = "byte",
				      "byte_intf",
				      "pixel",
				      "core",
				      "iface",
				      "bus";

			assigned-clocks = <&dispcc DISP_CC_MDSS_BYTE0_CLK_SRC>,
					  <&dispcc DISP_CC_MDSS_PCLK0_CLK_SRC>;
			assigned-clock-parents = <&mdss_dsi0_phy DSI_BYTE_PLL_CLK>,
						 <&mdss_dsi0_phy DSI_PIXEL_PLL_CLK>;

			operating-points-v2 = <&dsi_opp_table>;
			power-domains = <&rpmhpd RPMHPD_CX>;

			phys = <&mdss_dsi0_phy>;
			refgen-supply = <&refgen>;

			#address-cells = <1>;
			#size-cells = <0>;

			status = "disabled";

			ports {
				#address-cells = <1>;
				#size-cells = <0>;

				port@0 {
					reg = <0>;
					mdss_dsi0_in: endpoint {
						remote-endpoint = <&dpu_intf1_out>;
					};
				};

				port@1 {
					reg = <1>;
					mdss_dsi0_out: endpoint {
					};
				};
			};

			dsi_opp_table: opp-table {
				compatible = "operating-points-v2";

				opp-187500000 {
					opp-hz = /bits/ 64 <187500000>;
					required-opps = <&rpmhpd_opp_low_svs>;
				};

				opp-300000000 {
					opp-hz = /bits/ 64 <300000000>;
					required-opps = <&rpmhpd_opp_svs>;
				};

				opp-358000000 {
					opp-hz = /bits/ 64 <358000000>;
					required-opps = <&rpmhpd_opp_svs_l1>;
				};
			};
		};

		mdss_dsi0_phy: phy@ae94400 {
			compatible = "qcom,dsi-phy-7nm";
			reg = <0x0 0x0ae94400 0x0 0x200>,
			      <0x0 0x0ae94600 0x0 0x280>,
			      <0x0 0x0ae94900 0x0 0x260>;
			reg-names = "dsi_phy",
				    "dsi_phy_lane",
				    "dsi_pll";

			clocks = <&dispcc DISP_CC_MDSS_AHB_CLK>,
				 <&rpmhcc RPMH_CXO_CLK>;
			clock-names = "iface", "ref";

			#clock-cells = <1>;
			#phy-cells = <0>;

			status = "disabled";
		};

		mdss_dsi1: dsi@ae96000 {
			compatible = "qcom,sm7250-dsi-ctrl",
				     "qcom,mdss-dsi-ctrl";
			reg = <0x0 0x0ae96000 0x0 0x400>;
			reg-names = "dsi_ctrl";

			interrupt-parent = <&mdss>;
			interrupts = <5>;

			clocks = <&dispcc DISP_CC_MDSS_BYTE1_CLK>,
				 <&dispcc DISP_CC_MDSS_BYTE1_INTF_CLK>,
				 <&dispcc DISP_CC_MDSS_PCLK1_CLK>,
				 <&dispcc DISP_CC_MDSS_ESC1_CLK>,
				 <&dispcc DISP_CC_MDSS_AHB_CLK>,
				 <&gcc GCC_DISP_HF_AXI_CLK>;
			clock-names = "byte",
				      "byte_intf",
				      "pixel",
				      "core",
				      "iface",
				      "bus";

			assigned-clocks = <&dispcc DISP_CC_MDSS_BYTE1_CLK_SRC>,
					  <&dispcc DISP_CC_MDSS_PCLK1_CLK_SRC>;
			assigned-clock-parents = <&mdss_dsi1_phy DSI_BYTE_PLL_CLK>,
						 <&mdss_dsi1_phy DSI_PIXEL_PLL_CLK>;

			operating-points-v2 = <&dsi_opp_table>;
			power-domains = <&rpmhpd RPMHPD_CX>;

			phys = <&mdss_dsi1_phy>;
			refgen-supply = <&refgen>;

			#address-cells = <1>;
			#size-cells = <0>;

			status = "disabled";

			ports {
				#address-cells = <1>;
				#size-cells = <0>;

				port@0 {
					reg = <0>;
					mdss_dsi1_in: endpoint {
						remote-endpoint = <&dpu_intf2_out>;
					};
				};

				port@1 {
					reg = <1>;
					mdss_dsi1_out: endpoint {
					};
				};
			};
		};

		mdss_dsi1_phy: phy@ae96400 {
			compatible = "qcom,dsi-phy-7nm";
			reg = <0x0 0x0ae96400 0x0 0x200>,
			      <0x0 0x0ae96600 0x0 0x280>,
			      <0x0 0x0ae96900 0x0 0x260>;
			reg-names = "dsi_phy",
				    "dsi_phy_lane",
				    "dsi_pll";

			clocks = <&dispcc DISP_CC_MDSS_AHB_CLK>,
				 <&rpmhcc RPMH_CXO_CLK>;
			clock-names = "iface", "ref";

			#clock-cells = <1>;
			#phy-cells = <0>;

			status = "disabled";
		};
	};

	/* Live DT qcom,gpucc@3d90000 (SM8250 GPU clock controller, SM7250 PLL) */
	gpucc: clock-controller@3d90000 {
		compatible = "qcom,sm7250-gpucc";
		reg = <0x0 0x03d90000 0x0 0x9000>;
		clocks = <&rpmhcc RPMH_CXO_CLK>,
			 <&gcc GCC_GPU_GPLL0_CLK_SRC>,
			 <&gcc GCC_GPU_GPLL0_DIV_CLK_SRC>;
		clock-names = "bi_tcxo",
			      "gcc_gpu_gpll0_clk_src",
			      "gcc_gpu_gpll0_div_clk_src";
		#clock-cells = <1>;
		#reset-cells = <1>;
		#power-domain-cells = <1>;
	};

	/* Live DT kgsl-smmu@3da0000: SPI 673 global, 678-685 context */
	adreno_smmu: iommu@3da0000 {
		compatible = "qcom,sm7250-smmu-500", "qcom,adreno-smmu",
			     "qcom,smmu-500", "arm,mmu-500";
		reg = <0x0 0x03da0000 0x0 0x10000>;
		#iommu-cells = <2>;
		#global-interrupts = <1>;
		interrupts = <GIC_SPI 673 IRQ_TYPE_LEVEL_HIGH>,
			     <GIC_SPI 678 IRQ_TYPE_LEVEL_HIGH>,
			     <GIC_SPI 679 IRQ_TYPE_LEVEL_HIGH>,
			     <GIC_SPI 680 IRQ_TYPE_LEVEL_HIGH>,
			     <GIC_SPI 681 IRQ_TYPE_LEVEL_HIGH>,
			     <GIC_SPI 682 IRQ_TYPE_LEVEL_HIGH>,
			     <GIC_SPI 683 IRQ_TYPE_LEVEL_HIGH>,
			     <GIC_SPI 684 IRQ_TYPE_LEVEL_HIGH>,
			     <GIC_SPI 685 IRQ_TYPE_LEVEL_HIGH>;
		clocks = <&gpucc GPU_CC_AHB_CLK>,
			 <&gcc GCC_GPU_MEMNOC_GFX_CLK>,
			 <&gcc GCC_GPU_SNOC_DVM_GFX_CLK>;
		clock-names = "ahb", "bus", "iface";
		power-domains = <&gpucc GPU_CX_GDSC>;
	};

	/*
	 * WCN3990 (live DT qcom,icnss@18800000): CE0-CE11 in the icnss order,
	 * SMMU stream 0xc0, MSA at wlan_fw_mem. The firmware runs in the
	 * modem's wlan_pd; ath10k_snoc probes once the modem is up.
	 */
	wifi: wifi@18800000 {
		compatible = "qcom,wcn3990-wifi";
		reg = <0x0 0x18800000 0x0 0x800000>;
		reg-names = "membase";
		memory-region = <&wlan_fw_mem>;
		interrupts = <GIC_SPI 132 IRQ_TYPE_LEVEL_HIGH>,
			     <GIC_SPI 81 IRQ_TYPE_LEVEL_HIGH>,
			     <GIC_SPI 415 IRQ_TYPE_LEVEL_HIGH>,
			     <GIC_SPI 416 IRQ_TYPE_LEVEL_HIGH>,
			     <GIC_SPI 417 IRQ_TYPE_LEVEL_HIGH>,
			     <GIC_SPI 86 IRQ_TYPE_LEVEL_HIGH>,
			     <GIC_SPI 94 IRQ_TYPE_LEVEL_HIGH>,
			     <GIC_SPI 96 IRQ_TYPE_LEVEL_HIGH>,
			     <GIC_SPI 82 IRQ_TYPE_LEVEL_HIGH>,
			     <GIC_SPI 119 IRQ_TYPE_LEVEL_HIGH>,
			     <GIC_SPI 120 IRQ_TYPE_LEVEL_HIGH>,
			     <GIC_SPI 87 IRQ_TYPE_LEVEL_HIGH>;
		iommus = <&apps_smmu 0xc0 0x1>;
		qcom,msa-fixed-perm;

		vdd-0.8-cx-mx-supply = <&vreg_l1a_0p75>;
		vdd-1.8-xo-supply = <&vreg_l14a_1p88>;
		vdd-1.3-rfa-supply = <&vreg_l2c_1p3>;
		vdd-3.3-ch0-supply = <&vreg_l10c_3p3>;
		vdd-3.3-ch1-supply = <&vreg_l11c_3p3>;
	};
};

&apps_rsc {
	/*
	 * Only the UFS and USB HS PHY supplies (live DT phandles resolved):
	 * UFS vcc = pm8150a_l7 (2.7-3.3 V, vcc-voltage-level 2.952-2.96 V),
	 * vccq2 = pm8150_s4 (1.8 V), UFS PHY = pm8150_l5 + pm8150_l9,
	 * HS PHY = pm8150_l5 (asks 0.88 V), pm8150_l12, pm8150_l2.
	 */
	regulators-0 {
		compatible = "qcom,pm8150-rpmh-regulators";
		qcom,pmic-id = "a";

		vreg_s4a_1p8: smps4 {
			regulator-name = "vreg_s4a_1p8";
			regulator-min-microvolt = <1800000>;
			regulator-max-microvolt = <1800000>;
			/* main 1.8 V I/O rail */
			regulator-always-on;
		};

		/*
		 * WLAN CX/MX (live DT icnss vdd-cx-mx: pm8150_l1, 0.352-0.952 V,
		 * icnss sets no voltage). ath10k only enables its supplies.
		 */
		vreg_l1a_0p75: ldo1 {
			regulator-name = "vreg_l1a_0p75";
			regulator-min-microvolt = <752000>;
			regulator-max-microvolt = <952000>;
			regulator-initial-mode = <RPMH_REGULATOR_MODE_HPM>;
		};

		vreg_l2a_3p1: ldo2 {
			regulator-name = "vreg_l2a_3p1";
			regulator-min-microvolt = <3072000>;
			regulator-max-microvolt = <3072000>;
			regulator-initial-mode = <RPMH_REGULATOR_MODE_HPM>;
		};

		vreg_l5a_0p88: ldo5 {
			regulator-name = "vreg_l5a_0p88";
			regulator-min-microvolt = <880000>;
			regulator-max-microvolt = <880000>;
			regulator-initial-mode = <RPMH_REGULATOR_MODE_HPM>;
		};

		vreg_l9a_1p2: ldo9 {
			regulator-name = "vreg_l9a_1p2";
			regulator-min-microvolt = <1200000>;
			regulator-max-microvolt = <1200000>;
			regulator-initial-mode = <RPMH_REGULATOR_MODE_HPM>;
		};

		/* WLAN XO (icnss vdd-1.8-xo: pm8150_l14, 1.8 V by default) */
		vreg_l14a_1p88: ldo14 {
			regulator-name = "vreg_l14a_1p88";
			regulator-min-microvolt = <1800000>;
			regulator-max-microvolt = <1880000>;
			regulator-initial-mode = <RPMH_REGULATOR_MODE_HPM>;
		};

		/*
		 * Panel vdd, 3.0 V (pm8150_l16).
		 * Panel rail (live DT: only the DSI display uses it). No display
		 * driver yet: regulator-boot-on without a consumer makes the core
		 * switch it off in its unused-regulator cleanup (~30 s after
		 * boot), as downstream's proxy vote release does. Otherwise the
		 * bootloader's vote keeps the command-mode OLED showing the splash
		 * (burn-in; docs/log.md after Test 95).
		 */
		vreg_l16a_3p0: ldo16 {
			regulator-name = "vreg_l16a_3p0";
			regulator-min-microvolt = <3000000>;
			regulator-max-microvolt = <3000000>;
			regulator-boot-on;
		};

		vreg_l12a_1p8: ldo12 {
			regulator-name = "vreg_l12a_1p8";
			regulator-min-microvolt = <1800000>;
			regulator-max-microvolt = <1800000>;
			regulator-initial-mode = <RPMH_REGULATOR_MODE_HPM>;
		};

		/*
		 * Touch avdd (lito-redfin-touch: pm8150_l17 at 3.304 V, HPM,
		 * always-on downstream; its only user on redfin).
		 */
		vreg_l17a_3p3: ldo17 {
			regulator-name = "vreg_l17a_3p3";
			regulator-min-microvolt = <3304000>;
			regulator-max-microvolt = <3304000>;
			regulator-initial-mode = <RPMH_REGULATOR_MODE_HPM>;
		};
	};

	regulators-1 {
		compatible = "qcom,pm8150l-rpmh-regulators";
		qcom,pmic-id = "c";

		/*
		 * Panel vddio, 1.8 V (pm8150a_l1); consumer: the S6E3HC2 panel.
		 * regulator-boot-on: until the panel driver enables it, the core
		 * switches it off in its unused-regulator cleanup (~30 s after
		 * boot), as downstream's proxy vote release does. Otherwise the
		 * bootloader's vote keeps the command-mode OLED showing the splash
		 * (burn-in; docs/log.md after Test 95).
		 */
		vreg_l1c_1p8: ldo1 {
			regulator-name = "vreg_l1c_1p8";
			regulator-min-microvolt = <1800000>;
			regulator-max-microvolt = <1800000>;
			regulator-boot-on;
		};

		/* WLAN RFA (icnss vdd-1.3-rfa: pm8150a_l2, 1.144-1.328 V) */
		vreg_l2c_1p3: ldo2 {
			regulator-name = "vreg_l2c_1p3";
			regulator-min-microvolt = <1144000>;
			regulator-max-microvolt = <1328000>;
			regulator-initial-mode = <RPMH_REGULATOR_MODE_HPM>;
		};

		vreg_l7c_2p96: ldo7 {
			regulator-name = "vreg_l7c_2p96";
			regulator-min-microvolt = <2952000>;
			regulator-max-microvolt = <2960000>;
			regulator-initial-mode = <RPMH_REGULATOR_MODE_HPM>;
		};

		/* WLAN 3.3 V chains (icnss vdd-3.3-ch0/ch1: pm8150a_l10/l11) */
		vreg_l10c_3p3: ldo10 {
			regulator-name = "vreg_l10c_3p3";
			regulator-min-microvolt = <3000000>;
			regulator-max-microvolt = <3312000>;
			regulator-initial-mode = <RPMH_REGULATOR_MODE_HPM>;
		};

		vreg_l11c_3p3: ldo11 {
			regulator-name = "vreg_l11c_3p3";
			regulator-min-microvolt = <3000000>;
			regulator-max-microvolt = <3312000>;
			regulator-initial-mode = <RPMH_REGULATOR_MODE_HPM>;
		};
	};
};

/*
 * SMB5 charger. Without constant-charge-current-max-microamp the driver
 * programs a 1.5 A fast-charge current (DCP_CURRENT_UA), below stock.
 * The 80/70 limit uses its writable "status" (USBIN suspend).
 */
&pm7250b_charger {
	monitored-battery = <&battery>;
	status = "okay";
};

&pm7250b_qg {
	monitored-battery = <&battery>;
	/* Its status comes from the charger; unlinked it always says Discharging. */
	power-supplies = <&pm7250b_charger>;
	status = "okay";
};

/* reboot("bootloader") -> PON reason 0x2 -> ABL stays in fastboot */
&pon {
	mode-bootloader = <0x2>;
	mode-recovery = <0x1>;
};

&pon_pwrkey {
	status = "okay";
};

&pon_resin {
	linux,code = <KEY_VOLUMEDOWN>;
	status = "okay";
};

&qupv3_id_1 {
	/* Live DT qcom,qupv3_1_geni_se@9c0000: SMMU stream 0x23 */
	iommus = <&apps_smmu 0x23 0x0>;

	/*
	 * Live DT i2c@98c000 (QUP1 SE3, SPI 356, 400 kHz, GPIOs 46/47).
	 * It also carries both CS35L41 amps, the FSA4480, the P9382
	 * wireless charger, an EEPROM, the SLG51000 camera PMIC and two
	 * PAC193x monitors: only the haptics driver is described, and the
	 * bus is never scanned.
	 */
	/*
	 * Live DT i2c@984000 (QUP1 SE1, SPI 354, GPIOs 6/7 function qup11):
	 * the RT5514 microphone DSP at 0x57 and the NFC controller at 0x08
	 * (not described). Not scanned.
	 */
	i2c7: i2c@984000 {
		compatible = "qcom,geni-i2c";
		reg = <0x0 0x00984000 0x0 0x4000>;
		clock-names = "se";
		clocks = <&gcc GCC_QUPV3_WRAP1_S1_CLK>;
		interrupts = <GIC_SPI 354 IRQ_TYPE_LEVEL_HIGH>;
		power-domains = <&rpmhpd RPMHPD_CX>;
		operating-points-v2 = <&qup_opp_table>;
		pinctrl-names = "default";
		pinctrl-0 = <&qup_i2c7_default>;
		clock-frequency = <400000>;
		#address-cells = <1>;
		#size-cells = <0>;

		/*
		 * RT5514 (lito-redbull-audio: reset GPIO 91 high; its DMICs
		 * are powered by "Audio LDO Mic1/2", PM7250B GPIO 6 and
		 * PM8150L GPIO 6, see vreg_mic_ldo1/2). On this RT5514P the I2S
		 * stream comes from its DSP; its firmware is loaded over SPI
		 * (&spi4) by "DSP I2S Capture Switch" (local patch 0010, Test 172).
		 */
		rt5514: audio-codec@57 {
			compatible = "realtek,rt5514";
			reg = <0x57>;
			reset-gpios = <&tlmm 91 GPIO_ACTIVE_LOW>;
			pinctrl-names = "default";
			pinctrl-0 = <&rt5514_reset_default>;
			#sound-dai-cells = <1>;
		};
	};

	i2c9: i2c@98c000 {
		compatible = "qcom,geni-i2c";
		reg = <0x0 0x0098c000 0x0 0x4000>;
		clock-names = "se";
		clocks = <&gcc GCC_QUPV3_WRAP1_S3_CLK>;
		interrupts = <GIC_SPI 356 IRQ_TYPE_LEVEL_HIGH>;
		power-domains = <&rpmhpd RPMHPD_CX>;
		operating-points-v2 = <&qup_opp_table>;
		pinctrl-names = "default";
		pinctrl-0 = <&qup_i2c9_default>;
		clock-frequency = <400000>;
		#address-cells = <1>;
		#size-cells = <0>;

		/*
		 * Live DT drv2624@5a: NRST on PM7250B GPIO 1, LRA, open loop.
		 * The ti,* tuning values are copied as they are.
		 */
		/*
		 * Speaker amps (live DT cs35l41@40/41 + the PVT pinctrl of
		 * lito-v2-redfin-evt-audio): left reset PM8150L GPIO 11,
		 * right reset PM7250B GPIO 11 (the live reset-gpios of the
		 * right amp, PM8150L GPIO 10, is a Pixel 4a 5G leftover). The
		 * live IRQ of the left amp, PM7250B GPIO 5, is the panel
		 * reset: no amp IRQs for now. Boost values as live. The
		 * driver drives reset to 1 to run the amp: active high, as
		 * downstream's flag 0 (Test 146: ACTIVE_LOW kept both in reset,
		 * "Failed waiting for OTP_BOOT_DONE").
		 */
		speaker_l: audio-amplifier@40 {
			compatible = "cirrus,cs35l41";
			reg = <0x40>;
			reset-gpios = <&pm8150l_gpios 11 GPIO_ACTIVE_HIGH>;
			/*
			 * Amp GPIO2 = push-pull active-high interrupt (downstream
			 * gpio-config2 src-select 5); PVT pins per lito-v2-redfin-
			 * evt-audio (the older base DT's PM7250B GPIO 5 is the
			 * panel reset here).
			 */
			interrupts-extended = <&pm8150l_gpios 3 IRQ_TYPE_LEVEL_HIGH>;
			pinctrl-names = "default";
			pinctrl-0 = <&spk_l_irq_default>;
			cirrus,gpio2-src-select = <5>;
			cirrus,gpio2-output-enable;
			cirrus,boost-peak-milliamp = <3700>;
			cirrus,boost-ind-nanohenry = <1000>;
			cirrus,boost-cap-microfarad = <15>;
			cirrus,asp-sdout-hiz = <3>;
			sound-name-prefix = "L";
			#sound-dai-cells = <1>;
		};

		speaker_r: audio-amplifier@41 {
			compatible = "cirrus,cs35l41";
			reg = <0x41>;
			reset-gpios = <&pm7250b_gpios 11 GPIO_ACTIVE_HIGH>;
			/*
			 * Amp GPIO2 = push-pull active-high interrupt (downstream
			 * gpio-config2 src-select 5); PVT pins per lito-v2-redfin-
			 * evt-audio (the older base DT's PM7250B GPIO 5 is the
			 * panel reset here).
			 */
			interrupts-extended = <&pm7250b_gpios 8 IRQ_TYPE_LEVEL_HIGH>;
			pinctrl-names = "default";
			pinctrl-0 = <&spk_r_irq_default>;
			cirrus,gpio2-src-select = <5>;
			cirrus,gpio2-output-enable;
			cirrus,boost-peak-milliamp = <3700>;
			cirrus,boost-ind-nanohenry = <1000>;
			cirrus,boost-cap-microfarad = <15>;
			cirrus,asp-sdout-hiz = <3>;
			sound-name-prefix = "R";
			#sound-dai-cells = <1>;
		};

		haptics@5a {
			compatible = "ti,drv2624";
			reg = <0x5a>;
			reset-gpios = <&pm7250b_gpios 1 GPIO_ACTIVE_LOW>;
			ti,smart-loop = <1>;
			ti,actuator = <1>;
			ti,rated-voltage = <0x6d>;
			ti,odclamp-voltage = <0xa1>;
			ti,lra-frequency = <172>;
			ti,ol-lra-frequency = <155>;
			ti,bemf-factor = <0x96>;
			ti,bemf-gain = <0>;
			ti,loop-gain = <0>;
			ti,voltage-comp = <0x12>;
			ti,blanking-time = <2>;
			ti,idiss-time = <2>;
			ti,zc-det-time = <0>;
			ti,lra-wave-shape = <1>;
			ti,waveform-interval = <1>;
			ti,fb-brake-factor = <0>;
		};
	};
};

&tlmm {
	/*
	 * GPIOs 0-3 are the QUP SE1 SPI bus (lito-pinctrl qupv3_se1_spi),
	 * owned by TrustZone (fingerprint; disabled spi@884000 in the live
	 * DT). Any access from Linux hangs the bus until the watchdog resets
	 * the phone: each of the four alone does (Tests 66-81).
	 */
	gpio-reserved-ranges = <0 4>;

	/* Downstream lito-pinctrl qupv3_se0_spi_active (touch) */
	qup_spi0_default: qup-spi0-default-state {
		pins = "gpio42", "gpio43", "gpio44", "gpio45";
		function = "qup00";
		drive-strength = <6>;
		bias-disable;
	};

	/* Downstream lito-pinctrl qupv3_se4_spi_active (RT5514 DSP) */
	qup_spi4_default: qup-spi4-default-state {
		pins = "gpio29", "gpio30", "gpio31", "gpio32";
		function = "qup04";
		drive-strength = <6>;
		bias-disable;
	};

	/* Downstream lito-redbull-audio rt5514_handshake */
	rt5514_handshake_default: rt5514-handshake-default-state {
		pins = "gpio66";
		function = "gpio";
		drive-strength = <2>;
		output-high;
	};

	/* Downstream lito-redfin-touch sec_ts_irq_default */
	touch_irq_default: touch-irq-default-state {
		pins = "gpio9";
		function = "gpio";
		drive-strength = <2>;
		bias-disable;
	};

	/* sec_ts_switch_default: touch SPI bus master = AP (low) */
	touch_switch_default: touch-switch-default-state {
		pins = "gpio35";
		function = "gpio";
		drive-strength = <2>;
		bias-disable;
		output-low;
	};

	/* Live DT qupv3_se9_i2c_active */
	/* Downstream qupv3_se7_i2c_active */
	qup_i2c7_default: qup-i2c7-default-state {
		pins = "gpio6", "gpio7";
		function = "qup11";
		drive-strength = <2>;
		bias-disable;
	};

	/* Downstream rt5514_reset: out of reset */
	rt5514_reset_default: rt5514-reset-default-state {
		pins = "gpio91";
		function = "gpio";
		drive-strength = <2>;
		output-high;
	};

	/* Downstream pri_tdm_*_active (lito-redbull-audio): RT5514 TDM */
	pri_tdm_active: pri-tdm-active-state {
		pins = "gpio49", "gpio51", "gpio52";
		function = "pri_mi2s";
		drive-strength = <8>;
		bias-disable;
	};

	pri_tdm_ws_active: pri-tdm-ws-active-state {
		pins = "gpio50";
		function = "pri_mi2s_ws";
		drive-strength = <8>;
		bias-disable;
	};

	qup_i2c9_default: qup-i2c9-default-state {
		pins = "gpio46", "gpio47";
		function = "qup13";
		drive-strength = <2>;
		bias-disable;
	};

	/*
	 * Live DT qupv3_se5_{ctsrx,rts,tx}, except RX: pulled up as on the
	 * mainline sc7180 Chromebooks (same WCN3991, same GPIOs 38-41). While
	 * the module's TX is tri-stated (in-band sleep) a floating RX reads
	 * garbage; with bias-disable the first command after ~1 min idle got
	 * no reply and hci_qca crashed the chip (Test 99).
	 */
	qup_uart5_cts: qup-uart5-cts-state {
		pins = "gpio38";
		function = "qup05";
		drive-strength = <2>;
		bias-disable;
	};

	qup_uart5_rx: qup-uart5-rx-state {
		pins = "gpio41";
		function = "qup05";
		drive-strength = <2>;
		bias-pull-up;
	};

	qup_uart5_rts: qup-uart5-rts-state {
		pins = "gpio39";
		function = "qup05";
		drive-strength = <2>;
		bias-pull-down;
	};

	qup_uart5_tx: qup-uart5-tx-state {
		pins = "gpio40";
		function = "qup05";
		drive-strength = <2>;
		bias-pull-up;
	};
};

&ufs_mem_hc {
	reset-gpios = <&tlmm 146 GPIO_ACTIVE_LOW>;	/* ufs_reset pad */
	vcc-supply = <&vreg_l7c_2p96>;
	vccq2-supply = <&vreg_s4a_1p8>;
	status = "okay";
};

&ufs_mem_phy {
	vdda-phy-supply = <&vreg_l5a_0p88>;
	vdda-pll-supply = <&vreg_l9a_1p2>;
	status = "okay";
};

&usb_1 {
	dr_mode = "peripheral";
	maximum-speed = "high-speed";
	qcom,select-utmi-as-pipe-clk;
	status = "okay";
};

&usb_1_hsphy {
	vdda-pll-supply = <&vreg_l5a_0p88>;
	vdda18-supply = <&vreg_l12a_1p8>;
	vdda33-supply = <&vreg_l2a_3p1>;
	status = "okay";
};

/*
 * Display: Samsung S6E3HC2 on DSI0 (downstream lito-redfin-display.dtsi:
 * panel dsi_s6e3hc2_dvt_dsc_1080p_cmd, reset PM7250B GPIO 5, TE GPIO 10,
 * vddio L1C 1.8 V, vdd L16A 3.0 V; DSI vdda-1p2 L9A, PHY vdda-0p9 L5A).
 * The panel driver is local patch 0004.
 */
&mdss_dsi0 {
	vdda-supply = <&vreg_l9a_1p2>;
	status = "okay";

	panel: panel@0 {
		compatible = "samsung,s6e3hc2";
		reg = <0>;

		vddio-supply = <&vreg_l1c_1p8>;
		vdd-supply = <&vreg_l16a_3p0>;
		reset-gpios = <&pm7250b_gpios 5 GPIO_ACTIVE_LOW>;

		pinctrl-0 = <&panel_reset_default>, <&panel_te_default>;
		pinctrl-names = "default";

		port {
			panel_in: endpoint {
				remote-endpoint = <&mdss_dsi0_out>;
			};
		};
	};
};

&mdss_dsi0_out {
	data-lanes = <0 1 2 3>;
	remote-endpoint = <&panel_in>;
};

&mdss_dsi0_phy {
	vdds-supply = <&vreg_l5a_0p88>;
	status = "okay";
};

&pm7250b_gpios {
	/* downstream audio_ldo1: power source VIN1 */
	mic_ldo1_default: mic-ldo1-default-state {
		pins = "gpio6";
		function = "normal";
		power-source = <1>;
		output-high;
	};

	spk_r_irq_default: spk-r-irq-default-state {
		pins = "gpio8";
		function = "normal";
		input-enable;
		bias-pull-down;
		power-source = <1>;
	};

	/* Live DT disp_pins_default (output-low dropped: the driver owns it) */
	panel_reset_default: panel-reset-default-state {
		pins = "gpio5";
		function = PMIC_GPIO_FUNC_NORMAL;
		power-source = <1>;
		qcom,drive-strength = <PMIC_GPIO_STRENGTH_MED>;
		bias-disable;
	};
};

&tlmm {
	/* Panel TE into the MDP vsync input (downstream sde_te_active) */
	panel_te_default: panel-te-default-state {
		pins = "gpio10";
		function = "mdp_vsync";
		drive-strength = <2>;
		bias-pull-down;
	};
};

&pm8150l_gpios {
	mic_ldo2_default: mic-ldo2-default-state {
		pins = "gpio6";
		function = "normal";
		output-high;
	};

	spk_l_irq_default: spk-l-irq-default-state {
		pins = "gpio3";
		function = "normal";
		input-enable;
		bias-pull-down;
	};
};

/*
 * Sound (P6.4): speakers = two CS35L41 on quinary TDM RX 0, microphones
 * = the RT5514 on primary TDM TX 0 (downstream lito-redbull-audio
 * external-playback/capture-dai-link). Framing as the live DT
 * msm-dai-tdm groups: short sync, internal sync source, data delay 1.
 */
&q6afedai {
	dai@25 {
		reg = <PRIMARY_TDM_TX_0>;
		qcom,tdm-sync-mode = <0>;
		qcom,tdm-sync-src = <1>;
		qcom,tdm-data-out = <0>;
		qcom,tdm-invert-sync = <0>;
		qcom,tdm-data-delay = <1>;
		qcom,tdm-data-align = <0>;
	};

	dai@89 {
		reg = <QUINARY_TDM_TX_0>;
		qcom,tdm-sync-mode = <0>;
		qcom,tdm-sync-src = <1>;
		qcom,tdm-data-out = <0>;
		qcom,tdm-invert-sync = <0>;
		qcom,tdm-data-delay = <1>;
		qcom,tdm-data-align = <0>;
	};

	dai@88 {
		reg = <QUINARY_TDM_RX_0>;
		qcom,tdm-sync-mode = <0>;
		qcom,tdm-sync-src = <1>;
		qcom,tdm-data-out = <0>;
		qcom,tdm-invert-sync = <0>;
		qcom,tdm-data-delay = <1>;
		qcom,tdm-data-align = <0>;
	};
};

&q6asmdai {
	/* one DSP session per direction (nairo 0156) */
	dai@0 {
		reg = <MSM_FRONTEND_DAI_MULTIMEDIA1>;
		direction = <Q6ASM_DAI_RX>;
	};

	dai@1 {
		reg = <MSM_FRONTEND_DAI_MULTIMEDIA2>;
		direction = <Q6ASM_DAI_TX>;
	};
};

/ {
	/*
	 * "Audio LDO Mic1/Mic2" (downstream audio_ldo1/2-gpios): DMIC power,
	 * on whenever the board is up. Not gpio-hogs: this kernel's generic
	 * hog code takes the DT cell as the line offset without the chip's
	 * of_xlate, so on the SPMI GPIO blocks (numbered from 1) a hog lands
	 * on the next pin (Test 150: GPIO 7 driven high, GPIO 6 untouched).
	 */
	vreg_mic_ldo1: regulator-mic-ldo1 {
		compatible = "regulator-fixed";
		regulator-name = "mic_ldo1";
		gpio = <&pm7250b_gpios 6 GPIO_ACTIVE_HIGH>;
		enable-active-high;
		pinctrl-names = "default";
		pinctrl-0 = <&mic_ldo1_default>;
		regulator-always-on;
		regulator-boot-on;
	};

	vreg_mic_ldo2: regulator-mic-ldo2 {
		compatible = "regulator-fixed";
		regulator-name = "mic_ldo2";
		gpio = <&pm8150l_gpios 6 GPIO_ACTIVE_HIGH>;
		enable-active-high;
		pinctrl-names = "default";
		pinctrl-0 = <&mic_ldo2_default>;
		regulator-always-on;
		regulator-boot-on;
	};

	sound {
		compatible = "google,redfin-sndcard";
		model = "Google Pixel 5";
		pinctrl-names = "default";
		pinctrl-0 = <&quin_tdm_active>, <&pri_tdm_active>,
			    <&pri_tdm_ws_active>;

		mm1-dai-link {
			link-name = "MultiMedia1";

			cpu {
				sound-dai = <&q6asmdai MSM_FRONTEND_DAI_MULTIMEDIA1>;
			};
		};

		mm2-dai-link {
			link-name = "MultiMedia2";

			cpu {
				sound-dai = <&q6asmdai MSM_FRONTEND_DAI_MULTIMEDIA2>;
			};
		};

		speaker-dai-link {
			link-name = "Speaker Playback";

			cpu {
				sound-dai = <&q6afedai QUINARY_TDM_RX_0>;
			};

			codec {
				sound-dai = <&speaker_l 0>, <&speaker_r 0>;
			};

			platform {
				sound-dai = <&q6routing>;
			};
		};

		/* amp voltage/current sense (downstream QUIN_TDM_TX_0) */
		amp-sense-dai-link {
			link-name = "Amp Sense Capture";

			cpu {
				sound-dai = <&q6afedai QUINARY_TDM_TX_0>;
			};

			codec {
				sound-dai = <&speaker_l 0>, <&speaker_r 0>;
			};

			platform {
				sound-dai = <&q6routing>;
			};
		};

		mic-dai-link {
			link-name = "Mic Capture";

			cpu {
				sound-dai = <&q6afedai PRIMARY_TDM_TX_0>;
			};

			codec {
				sound-dai = <&rt5514 0>;
			};

			platform {
				sound-dai = <&q6routing>;
			};
		};
	};
};
